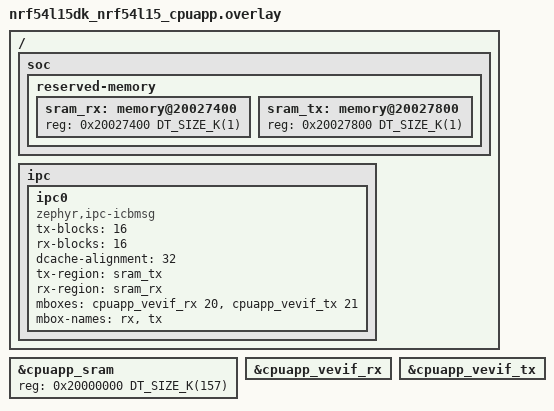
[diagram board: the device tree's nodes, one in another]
/*
 * Copyright (c) 2026 Nordic Semiconductor ASA
 *
 * SPDX-License-Identifier: Apache-2.0
 */

/* 256k RAM layout:
 * - 157k APP RAM
 * - 2k APP-FLPR IPC communication
 * - 96k FLPR Code
 * - 1k FLPR Hibernation space
 */

/ {
	soc {
		reserved-memory {
			#address-cells = <1>;
			#size-cells = <1>;

			sram_rx: memory@20027400 {
				reg = <0x20027400 DT_SIZE_K(1)>;
			};

			sram_tx: memory@20027800 {
				reg = <0x20027800 DT_SIZE_K(1)>;
			};
		};
	};

	ipc {
		ipc0: ipc0 {
			compatible = "zephyr,ipc-icbmsg";
			tx-blocks = <16>;
			rx-blocks = <16>;
			dcache-alignment = <32>;
			tx-region = <&sram_tx>;
			rx-region = <&sram_rx>;
			mboxes = <&cpuapp_vevif_rx 20>, <&cpuapp_vevif_tx 21>;
			mbox-names = "rx", "tx";
			status = "okay";
		};
	};
};

&cpuapp_sram {
	reg = <0x20000000 DT_SIZE_K(157)>;
	ranges = <0x0 0x20000000 DT_SIZE_K(157)>;
};

&cpuapp_vevif_rx {
	status = "okay";
};

&cpuapp_vevif_tx {
	status = "okay";
};
